AUTOSAR XML (schema 00053)
package /MICROSAR/BswM_swc
  7 x mode declaration group, all with category=EXPLICIT_ORDER, on-transition-value=2:
    ESH_RunRequest: initial-mode=RELEASED
      mode RELEASED: value=0
      mode REQUESTED: value=1
    SDC_SdEventHandlerState: initial-mode=SDC_EH_RELEASED
      mode SDC_EH_RELEASED: value=0
      mode SDC_EH_REQUESTED: value=1
    SDC_SdClientServiceState: initial-mode=SDC_CLIENT_DOWN
      mode SDC_CLIENT_DOWN: value=0
      mode SDC_CLIENT_AVAILABLE: value=1
    SDC_SdConsumedEventGroupRequest: initial-mode=SDC_CEG_RELEASED
      mode SDC_CEG_RELEASED: value=0
      mode SDC_CEG_REQUESTED: value=1
    SDC_SdServerServiceRequest: initial-mode=SDC_SERVER_DOWN
      mode SDC_SERVER_DOWN: value=0
      mode SDC_SERVER_AVAILABE: value=1
    SDC_SdConsumedEventGroupState: initial-mode=SDC_CEG_DOWN
      mode SDC_CEG_DOWN: value=0
      mode SDC_CEG_AVAILABLE: value=1
    SDC_SdClientServiceRequest: initial-mode=SDC_CLIENT_RELEASED
      mode SDC_CLIENT_RELEASED: value=0
      mode SDC_CLIENT_REQUESTED: value=1
  data type mapping set BswMMappingSet  # Contains Mapping for ModeDeclarations Groups which are provided by BswM.
    mode-request-type-maps:
      implementation-data-type=BswM_ESH_RunRequest, mode-group=ESH_RunRequest
      implementation-data-type=BswM_SDC_SdEventHandlerState, mode-group=SDC_SdEventHandlerState
      implementation-data-type=BswM_SDC_SdClientServiceState, mode-group=SDC_SdClientServiceState
      implementation-data-type=BswM_SDC_SdConsumedEventGroupRequest, mode-group=SDC_SdConsumedEventGroupRequest
      implementation-data-type=BswM_SDC_SdServerServiceRequest, mode-group=SDC_SdServerServiceRequest
      implementation-data-type=BswM_SDC_SdConsumedEventGroupState, mode-group=SDC_SdConsumedEventGroupState
      implementation-data-type=BswM_SDC_SdClientServiceRequest, mode-group=SDC_SdClientServiceRequest
      implementation-data-type=Dcm_EcuResetType, mode-group=DcmEcuReset
package /MICROSAR/BswM_swc/DataTypes
  7 x impl type, all with category=TYPE_REFERENCE, range raw 0..255, implementation-data-type=uint8:
    BswM_ESH_RunRequest: compu {0=RELEASED, 1=REQUESTED}  # Unique value for each user
    BswM_SDC_SdEventHandlerState: compu {0=SDC_EH_RELEASED, 1=SDC_EH_REQUESTED}  # Unique value for each user
    BswM_SDC_SdClientServiceState: compu {0=SDC_CLIENT_DOWN, 1=SDC_CLIENT_AVAILABLE}  # Unique value for each user
    BswM_SDC_SdConsumedEventGroupRequest: compu {0=SDC_CEG_RELEASED, 1=SDC_CEG_REQUESTED}  # Unique value for each user
    BswM_SDC_SdServerServiceRequest: compu {0=SDC_SERVER_DOWN, 1=SDC_SERVER_AVAILABE}  # Unique value for each user
    BswM_SDC_SdConsumedEventGroupState: compu {0=SDC_CEG_DOWN, 1=SDC_CEG_AVAILABLE}  # Unique value for each user
    BswM_SDC_SdClientServiceRequest: compu {0=SDC_CLIENT_RELEASED, 1=SDC_CLIENT_REQUESTED}  # Unique value for each user
package /MICROSAR/BswM_swc/Interfaces
  mode switch interface BswM_MSI_ESH_RunRequest: is-service=true, service-kind=BASIC-SOFTWARE-MODE-MANAGER
    mode group BswM_MDGP_ESH_RunRequest: type=ESH_RunRequest
  sender receiver interface BswM_SRI_BswM_MSI_ESH_RunRequest_BswM_MDGP_ESH_RunRequest: is-service=true, service-kind=BASIC-SOFTWARE-MODE-MANAGER
    data requestedMode: type=BswM_ESH_RunRequest
  mode switch interface BswM_MSI_SDC_SdEventHandlerState: is-service=true, service-kind=BASIC-SOFTWARE-MODE-MANAGER
    mode group BswM_MDGP_SDC_SdEventHandlerState: type=SDC_SdEventHandlerState
  sender receiver interface BswM_SRI_BswM_MSI_SDC_SdEventHandlerState_BswM_MDGP_SDC_SdEventHandlerState: is-service=true, service-kind=BASIC-SOFTWARE-MODE-MANAGER
    data requestedMode: type=BswM_SDC_SdEventHandlerState
  mode switch interface BswM_MSI_SDC_SdClientServiceState: is-service=true, service-kind=BASIC-SOFTWARE-MODE-MANAGER
    mode group BswM_MDGP_SDC_SdClientServiceState: type=SDC_SdClientServiceState
  sender receiver interface BswM_SRI_BswM_MSI_SDC_SdClientServiceState_BswM_MDGP_SDC_SdClientServiceState: is-service=true, service-kind=BASIC-SOFTWARE-MODE-MANAGER
    data requestedMode: type=BswM_SDC_SdClientServiceState
  mode switch interface BswM_MSI_SDC_SdConsumedEventGroupRequest: is-service=true, service-kind=BASIC-SOFTWARE-MODE-MANAGER
    mode group BswM_MDGP_SDC_SdConsumedEventGroupRequest: type=SDC_SdConsumedEventGroupRequest
  sender receiver interface BswM_SRI_BswM_MSI_SDC_SdConsumedEventGroupRequest_BswM_MDGP_SDC_SdConsumedEventGroupRequest: is-service=true, service-kind=BASIC-SOFTWARE-MODE-MANAGER
    data requestedMode: type=BswM_SDC_SdConsumedEventGroupRequest
  mode switch interface BswM_MSI_SDC_SdServerServiceRequest: is-service=true, service-kind=BASIC-SOFTWARE-MODE-MANAGER
    mode group BswM_MDGP_SDC_SdServerServiceRequest: type=SDC_SdServerServiceRequest
  sender receiver interface BswM_SRI_BswM_MSI_SDC_SdServerServiceRequest_BswM_MDGP_SDC_SdServerServiceRequest: is-service=true, service-kind=BASIC-SOFTWARE-MODE-MANAGER
    data requestedMode: type=BswM_SDC_SdServerServiceRequest
  mode switch interface BswM_MSI_SDC_SdConsumedEventGroupState: is-service=true, service-kind=BASIC-SOFTWARE-MODE-MANAGER
    mode group BswM_MDGP_SDC_SdConsumedEventGroupState: type=SDC_SdConsumedEventGroupState
  sender receiver interface BswM_SRI_BswM_MSI_SDC_SdConsumedEventGroupState_BswM_MDGP_SDC_SdConsumedEventGroupState: is-service=true, service-kind=BASIC-SOFTWARE-MODE-MANAGER
    data requestedMode: type=BswM_SDC_SdConsumedEventGroupState
  mode switch interface BswM_MSI_SDC_SdClientServiceRequest: is-service=true, service-kind=BASIC-SOFTWARE-MODE-MANAGER
    mode group BswM_MDGP_SDC_SdClientServiceRequest: type=SDC_SdClientServiceRequest
  sender receiver interface BswM_SRI_BswM_MSI_SDC_SdClientServiceRequest_BswM_MDGP_SDC_SdClientServiceRequest: is-service=true, service-kind=BASIC-SOFTWARE-MODE-MANAGER
    data requestedMode: type=BswM_SDC_SdClientServiceRequest
package /MICROSAR/BswM_swc/ComponentTypes
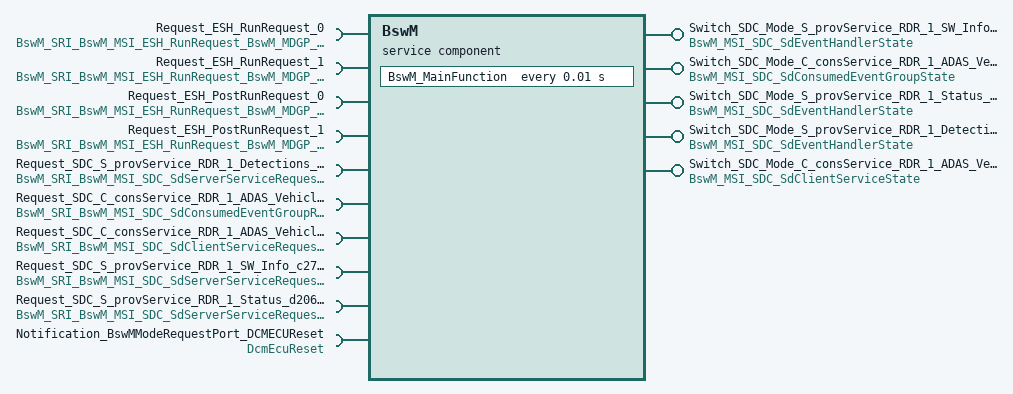
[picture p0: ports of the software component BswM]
  service sw component type BswM: category=SERVICE_COMPONENT
    4 x require port, all with nonqueued-receiver-com-spec{data-element=BswM_SRI_BswM_MSI_ESH_RunRequest_BswM_MDGP_ESH_RunRequest/requestedMode, handle-out-of-range-status=SILENT, init-value=RELEASED}, required-interface=BswM_SRI_BswM_MSI_ESH_RunRequest_BswM_MDGP_ESH_RunRequest:
      Request_ESH_RunRequest_0
      Request_ESH_RunRequest_1
      Request_ESH_PostRunRequest_0
      Request_ESH_PostRunRequest_1
    5 x provide port:
      Switch_SDC_Mode_S_provService_RDR_1_SW_Info_c2745ec9_EH_EventGroup_RDR_1_653e2581: provided-interface=BswM_MSI_SDC_SdEventHandlerState
      Switch_SDC_Mode_C_consService_RDR_1_ADAS_Vehicle_Status_2b1e055b_CEG_consServiceGrp_RDR_1_ADAS_Vehicle_Status_4b79da85: provided-interface=BswM_MSI_SDC_SdConsumedEventGroupState
      Switch_SDC_Mode_S_provService_RDR_1_Status_d2069d01_EH_EventGroup_RDR_1_f7c73cae: provided-interface=BswM_MSI_SDC_SdEventHandlerState
      Switch_SDC_Mode_S_provService_RDR_1_Detections_89f78c9f_EH_EventGroup_RDR_1_ca62382d: provided-interface=BswM_MSI_SDC_SdEventHandlerState
      Switch_SDC_Mode_C_consService_RDR_1_ADAS_Vehicle_Status_2b1e055b: provided-interface=BswM_MSI_SDC_SdClientServiceState
    6 x require port:
      Request_SDC_S_provService_RDR_1_Detections_89f78c9f: nonqueued-receiver-com-spec{data-element=BswM_SRI_BswM_MSI_SDC_SdServerServiceRequest_BswM_MDGP_SDC_SdServerServiceRequest/requestedMode, handle-out-of-range-status=SILENT, init-value=SDC_SERVER_DOWN}, required-interface=BswM_SRI_BswM_MSI_SDC_SdServerServiceRequest_BswM_MDGP_SDC_SdServerServiceRequest
      Request_SDC_C_consService_RDR_1_ADAS_Vehicle_Status_2b1e055b_CEG_consServiceGrp_RDR_1_ADAS_Vehicle_Status_4b79da85: nonqueued-receiver-com-spec{data-element=BswM_SRI_BswM_MSI_SDC_SdConsumedEventGroupRequest_BswM_MDGP_SDC_SdConsumedEventGroupRequest/requestedMode, handle-out-of-range-status=SILENT, init-value=SDC_CEG_RELEASED}, required-interface=BswM_SRI_BswM_MSI_SDC_SdConsumedEventGroupRequest_BswM_MDGP_SDC_SdConsumedEventGroupRequest
      Request_SDC_C_consService_RDR_1_ADAS_Vehicle_Status_2b1e055b: nonqueued-receiver-com-spec{data-element=BswM_SRI_BswM_MSI_SDC_SdClientServiceRequest_BswM_MDGP_SDC_SdClientServiceRequest/requestedMode, handle-out-of-range-status=SILENT, init-value=SDC_CLIENT_RELEASED}, required-interface=BswM_SRI_BswM_MSI_SDC_SdClientServiceRequest_BswM_MDGP_SDC_SdClientServiceRequest
      Request_SDC_S_provService_RDR_1_SW_Info_c2745ec9: nonqueued-receiver-com-spec{data-element=BswM_SRI_BswM_MSI_SDC_SdServerServiceRequest_BswM_MDGP_SDC_SdServerServiceRequest/requestedMode, handle-out-of-range-status=SILENT, init-value=SDC_SERVER_DOWN}, required-interface=BswM_SRI_BswM_MSI_SDC_SdServerServiceRequest_BswM_MDGP_SDC_SdServerServiceRequest
      Request_SDC_S_provService_RDR_1_Status_d2069d01: nonqueued-receiver-com-spec{data-element=BswM_SRI_BswM_MSI_SDC_SdServerServiceRequest_BswM_MDGP_SDC_SdServerServiceRequest/requestedMode, handle-out-of-range-status=SILENT, init-value=SDC_SERVER_DOWN}, required-interface=BswM_SRI_BswM_MSI_SDC_SdServerServiceRequest_BswM_MDGP_SDC_SdServerServiceRequest
      Notification_BswMModeRequestPort_DCMECUReset: required-interface=DcmEcuReset
    behavior BswMInternalBehavior: data-type-mapping=BswMMappingSet, handle-termination-and-restart=NO-SUPPORT, included-data-type-set=data-type=[BswM_ESH_RunRequest, BswM_SDC_SdEventHandlerState, BswM_SDC_SdClientServiceState, BswM_SDC_SdConsumedEventGroupRequest, BswM_SDC_SdServerServiceRequest, BswM_SDC_SdConsumedEventGroupState, BswM_SDC_SdClientServiceRequest]
      timing event Timer_BswM_MainFunction: start-on-event=BswM_MainFunction, period=0.01
      port-api-options:
        enable-take-address=true, indirect-api=false, port=Switch_SDC_Mode_S_provService_RDR_1_SW_Info_c2745ec9_EH_EventGroup_RDR_1_653e2581
        enable-take-address=true, indirect-api=false, port=Switch_SDC_Mode_C_consService_RDR_1_ADAS_Vehicle_Status_2b1e055b_CEG_consServiceGrp_RDR_1_ADAS_Vehicle_Status_4b79da85
        enable-take-address=true, indirect-api=false, port=Switch_SDC_Mode_S_provService_RDR_1_Status_d2069d01_EH_EventGroup_RDR_1_f7c73cae
        enable-take-address=true, indirect-api=false, port=Switch_SDC_Mode_S_provService_RDR_1_Detections_89f78c9f_EH_EventGroup_RDR_1_ca62382d
        enable-take-address=true, indirect-api=false, port=Switch_SDC_Mode_C_consService_RDR_1_ADAS_Vehicle_Status_2b1e055b
        enable-take-address=true, indirect-api=false, port=Request_ESH_RunRequest_0
        enable-take-address=true, indirect-api=false, port=Request_ESH_RunRequest_1
        enable-take-address=true, indirect-api=false, port=Request_ESH_PostRunRequest_0
        enable-take-address=true, indirect-api=false, port=Request_ESH_PostRunRequest_1
        enable-take-address=true, indirect-api=false, port=Request_SDC_S_provService_RDR_1_Detections_89f78c9f
        enable-take-address=true, indirect-api=false, port=Request_SDC_C_consService_RDR_1_ADAS_Vehicle_Status_2b1e055b_CEG_consServiceGrp_RDR_1_ADAS_Vehicle_Status_4b79da85
        enable-take-address=true, indirect-api=false, port=Request_SDC_C_consService_RDR_1_ADAS_Vehicle_Status_2b1e055b
        enable-take-address=true, indirect-api=false, port=Request_SDC_S_provService_RDR_1_SW_Info_c2745ec9
        enable-take-address=true, indirect-api=false, port=Request_SDC_S_provService_RDR_1_Status_d2069d01
        enable-take-address=true, indirect-api=false, port=Notification_BswMModeRequestPort_DCMECUReset
      runnable BswM_MainFunction: sw-addr-method=CODE_ASIL_D, mode-access-point=Notification_BswMModeRequestPort_DCMECUReset.DcmEcuReset
        data-receive-point-by-arguments:
          9 x access:
            DataReceivePointBswM_MainFunction_Request_ESH_RunRequest_0_requestedMode: accessed-variable=Request_ESH_RunRequest_0.requestedMode
            DataReceivePointBswM_MainFunction_Request_ESH_RunRequest_1_requestedMode: accessed-variable=Request_ESH_RunRequest_1.requestedMode
            DataReceivePointBswM_MainFunction_Request_ESH_PostRunRequest_0_requestedMode: accessed-variable=Request_ESH_PostRunRequest_0.requestedMode
            DataReceivePointBswM_MainFunction_Request_ESH_PostRunRequest_1_requestedMode: accessed-variable=Request_ESH_PostRunRequest_1.requestedMode
            DataReceivePointBswM_MainFunction_Request_SDC_S_provService_RDR_1_Detections_89f78c9f_requestedMode: accessed-variable=Request_SDC_S_provService_RDR_1_Detections_89f78c9f.requestedMode
            DataReceivePointBswM_MainFunction_Request_SDC_C_consService_RDR_1_ADAS_Vehicle_Status_2b1e055b_CEG_consServiceGrp_RDR_1_ef66e980: accessed-variable=Request_SDC_C_consService_RDR_1_ADAS_Vehicle_Status_2b1e055b_CEG_consServiceGrp_RDR_1_ADAS_Vehicle_Status_4b79da85.requestedMode
            DataReceivePointBswM_MainFunction_Request_SDC_C_consService_RDR_1_ADAS_Vehicle_Status_2b1e055b_requestedMode: accessed-variable=Request_SDC_C_consService_RDR_1_ADAS_Vehicle_Status_2b1e055b.requestedMode
            DataReceivePointBswM_MainFunction_Request_SDC_S_provService_RDR_1_SW_Info_c2745ec9_requestedMode: accessed-variable=Request_SDC_S_provService_RDR_1_SW_Info_c2745ec9.requestedMode
            DataReceivePointBswM_MainFunction_Request_SDC_S_provService_RDR_1_Status_d2069d01_requestedMode: accessed-variable=Request_SDC_S_provService_RDR_1_Status_d2069d01.requestedMode
        5 x mode switch point:
          ModeSwitchPointBswM_MainFunction_Switch_SDC_Mode_S_provService_RDR_1_SW_Info_c2745ec9_EH_EventGroup_RDR_1_653e2581_BswM_bfd69607: mode-group=Switch_SDC_Mode_S_provService_RDR_1_SW_Info_c2745ec9_EH_EventGroup_RDR_1_653e2581.BswM_MDGP_SDC_SdEventHandlerState
          ModeSwitchPointBswM_MainFunction_Switch_SDC_Mode_C_consService_RDR_1_ADAS_Vehicle_Status_2b1e055b_CEG_consServiceGrp_RD_a98e052d: mode-group=Switch_SDC_Mode_C_consService_RDR_1_ADAS_Vehicle_Status_2b1e055b_CEG_consServiceGrp_RDR_1_ADAS_Vehicle_Status_4b79da85.BswM_MDGP_SDC_SdConsumedEventGroupState
          ModeSwitchPointBswM_MainFunction_Switch_SDC_Mode_S_provService_RDR_1_Status_d2069d01_EH_EventGroup_RDR_1_f7c73cae_BswM_a9763b78: mode-group=Switch_SDC_Mode_S_provService_RDR_1_Status_d2069d01_EH_EventGroup_RDR_1_f7c73cae.BswM_MDGP_SDC_SdEventHandlerState
          ModeSwitchPointBswM_MainFunction_Switch_SDC_Mode_S_provService_RDR_1_Detections_89f78c9f_EH_EventGroup_RDR_1_ca62382d_B_a683091b: mode-group=Switch_SDC_Mode_S_provService_RDR_1_Detections_89f78c9f_EH_EventGroup_RDR_1_ca62382d.BswM_MDGP_SDC_SdEventHandlerState
          ModeSwitchPointBswM_MainFunction_Switch_SDC_Mode_C_consService_RDR_1_ADAS_Vehicle_Status_2b1e055b_BswM_MDGP_SDC_SdClien_e479842c: mode-group=Switch_SDC_Mode_C_consService_RDR_1_ADAS_Vehicle_Status_2b1e055b.BswM_MDGP_SDC_SdClientServiceState
  swc implementation BswMImplementation: programming-language=C, behavior=BswMInternalBehavior
    resource consumption BswMResourceConsumption
      memory section CODE_ASIL_D: sw-addrmethod=CODE_ASIL_D
